# psc3 register map
Vendor: Infineon Technologies; Series: PSC3; File version: 1.0
CPU: CM33 r0p1, little endian, MPU, FPU, VTOR, 3 interrupt priority bits
Registers are 32-bit, read-write, reset 0x0 unless marked. A register's access mark holds for its fields unless they carry their own. Offsets are from the block's base; [hi:lo] are bit positions; {n}, {i} and the like mark numbered series; 'fields as' and 'values as' point back to an identical list.

## SRSS (part 1 of 3) — SRSS Core Registers
Base 0x42200000
0x40 PWR_LVD_STATUS ro — High Voltage / Low Voltage Detector (HVLVD) Status Register
  [0] HVLVD1_OK — HVLVD1 output. 0: below voltage threshold 1: above voltage threshold
0x44 PWR_LVD_STATUS2 ro — High Voltage / Low Voltage Detector (HVLVD) Status Register #2
  [0] HVLVD2_OUT — HVLVD2 output. 0: below voltage threshold 1: above voltage threshold
{0x100+4i} CLK_DSI_SELECT[{i}] (i=0..15) — Clock DSI Select Register
  [4:0] DSI_MUX — Selects a DSI source or low frequency clock for use in a clock path. The output of this mux can be selected for clock PATH<i> using CLK_SELECT_PATH register. Using the output of this mux as HFCLK source will result in undefined behavior. It can be used to clocks to DSI or as reference inputs for the FLL/PLL, subject to the frequency limits of those circuits. This mux is not glitch free, so do not change the selection while it is an actively selected clock.
    {v}=DSI_OUT{v} (DSI{v} - dsi_out[{v}]) (v=0..15); 16=ILO (ILO - Internal Low-speed Oscillator #0); 17=WCO (WCO - Watch-Crystal Oscillator); 18=ALTLF (ALTLF - Alternate Low-Frequency Clock); 19=PILO (PILO - Precision Internal Low-speed Oscillator); 20=ILO1 (ILO1 - Internal Low-speed Oscillator #1, if present.)
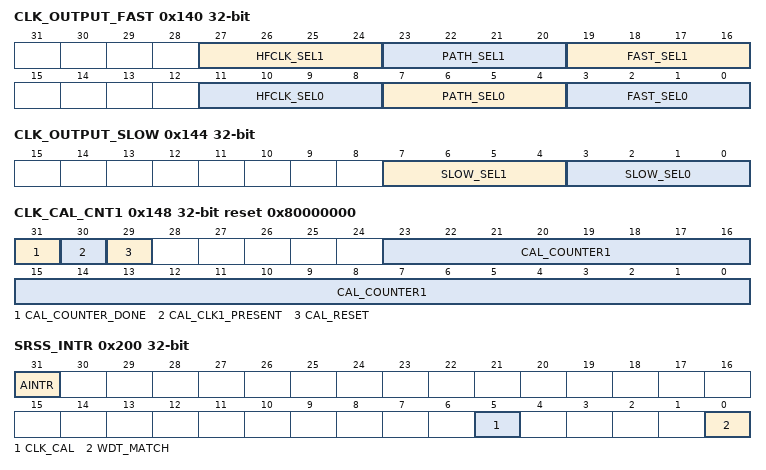
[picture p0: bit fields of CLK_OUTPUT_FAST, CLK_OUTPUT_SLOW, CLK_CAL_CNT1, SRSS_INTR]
0x140 CLK_OUTPUT_FAST — Fast Clock Output Select Register
  [27:24] HFCLK_SEL1 — Selects a HFCLK tree for use in fast clock output #1 logic
  [23:20] PATH_SEL1 — Selects a clock path to use in fast clock output #1 logic.
  [19:16] FAST_SEL1 — Select signal for fast clock output #1
    0=NC (Disabled - output is 0. For power savings, clocks are blocked before entering any muxes, including PATH_SEL1 and HFCLK_SEL1.); 1=ECO (External Crystal Oscillator (ECO)); 2=EXTCLK (External clock input (EXTCLK)); 3=ALTHF (Alternate High-Frequency (ALTHF) clock input to SRSS); 4=TIMERCLK (Timer clock. It is grouped with the fast clocks because it may be a gated version of a fast clock, and therefore may have a short high pulse.); 5=PATH_SEL1 (Selects the clock path chosen by PATH_SEL1 field); 6=HFCLK_SEL1 (Selects the output of the HFCLK_SEL1 mux); 7=SLOW_SEL1 (Selects the output of CLK_OUTPUT_SLOW.SLOW_SEL1); 8=IHO (Internal High-speed Oscillator (IHO).); 9=PWR (clk_pwr: used for PPU and related components)
  [11:8] HFCLK_SEL0 — Selects a HFCLK tree for use in fast clock output #0
  [7:4] PATH_SEL0 — Selects a clock path to use in fast clock output #0 logic.
  [3:0] FAST_SEL0 — Select signal for fast clock output #0
    0=NC (Disabled - output is 0. For power savings, clocks are blocked before entering any muxes, including PATH_SEL0 and HFCLK_SEL0.); 1=ECO (External Crystal Oscillator (ECO)); 2=EXTCLK (External clock input (EXTCLK)); 3=ALTHF (Alternate High-Frequency (ALTHF) clock input to SRSS); 4=TIMERCLK (Timer clock. It is grouped with the fast clocks because it may be a gated version of a fast clock, and therefore may have a short high pulse.); 5=PATH_SEL0 (Selects the clock path chosen by PATH_SEL0 field); 6=HFCLK_SEL0 (Selects the output of the HFCLK_SEL0 mux); 7=SLOW_SEL0 (Selects the output of CLK_OUTPUT_SLOW.SLOW_SEL0); 8=IHO (Internal High-speed Oscillator (IHO).); 9=PWR (clk_pwr: used for PPU and related components)
0x144 CLK_OUTPUT_SLOW — Slow Clock Output Select Register
  [7:4] SLOW_SEL1 — Select signal for slow clock output #1
    0=NC (Disabled - output is 0. For power savings, clocks are blocked before entering any muxes.); 1=ILO (Internal Low Speed Oscillator (ILO)); 2=WCO (Watch-Crystal Oscillator (WCO)); 3=BAK (Root of the Backup domain clock tree (BAK)); 4=ALTLF (Alternate low-frequency clock input to SRSS (ALTLF)); 5=LFCLK (Root of the low-speed clock tree (LFCLK)); 6=IMO (Internal Main Oscillator (IMO). This is grouped with the slow clocks so it can be observed during DEEPSLEEP entry/exit.); 7=SLPCTRL (Sleep Controller clock (SLPCTRL). This is grouped with the slow clocks so it can be observed during DEEPSLEEP entry/exit.); 8=PILO (Precision Internal Low Speed Oscillator (PILO)); 9=ILO1 (Internal Low Speed Oscillator (ILO1), if present on the product.); 10=ECO_PRESCALER (ECO Prescaler (ECO_PRESCALER)); 11=LPECO; 12=LPECO_PRESCALER (LPECO Prescaler (LPECO_PRESCALER)); 13=MFO (Medium Frequency Oscillator (MFO))
  [3:0] SLOW_SEL0 — Select signal for slow clock output #0
    values as SLOW_SEL1
0x148 CLK_CAL_CNT1 reset 0x80000000 — Clock Calibration Counter 1
  [31] CAL_COUNTER_DONE ro — Status bit indicating that the internal counter #1 is finished counting and CLK_CAL_CNT2.COUNTER stopped counting up
  [30] CAL_CLK1_PRESENT ro — Status bit indicating that a posedge was detected by counter #1. If this bit never asserts, there is no clock on counter #1 and CAL_COUNTER_DONE will stay low indefinitely. This can be recovered with CAL_RESET.
  [29] CAL_RESET — Reset clock calibration logic for window mode. This can be used to recover from unexpected conditions, such as no clock present on counter #1. Set this bit only when CLK_CAL_TEST.CAL_WINDOW_SEL=1 (window mode). It takes 3 clock cycles for reset to propagate.
  [23:0] CAL_COUNTER1 — Down-counter clocked on fast clock output #0 (see CLK_OUTPUT_FAST). This register always reads as zero. Counting starts internally when this register is written with a nonzero value. CAL_COUNTER_DONE goes immediately low to indicate that the counter has started and will be asserted when the counters are done. Do not write this field unless CAL_COUNTER_DONE==1. Both clocks must be running or the measurement will not complete, and this case can be recovered using CAL_RESET.
0x14C CLK_CAL_CNT2 ro — Clock Calibration Counter 2
  [23:0] CAL_COUNTER2 — Up-counter clocked on fast clock output #1 (see CLK_OUTPUT_FAST). When CLK_CAL_CNT1.CAL_COUNTER_DONE==1, the counter is stopped and can be read by SW. Do not read this value unless CAL_COUNTER_DONE==1. The expected final value is related to the ratio of clock frequencies used for the two counters and the value loaded into counter 1: CLK_CAL_CNT2.COUNTER=(F_cnt2/F_cnt1)*(CLK_CAL_CNT1.COUNTER)
0x200 SRSS_INTR — SRSS Interrupt Register
  [31] AINTR ro — See additional interrupts in SRSS_AINTR.
  [5] CLK_CAL — Clock calibration counter is done. This field is reset during DEEPSLEEP mode.
  [0] WDT_MATCH — WDT Interrupt Request. This bit is set each time WDT_COUNTR==WDT_MATCH. W1C also feeds the watch dog. Missing 2 interrupts in a row will generate a reset. Due to internal synchronization, it takes 2 SYSCLK cycles to update after a W1C.
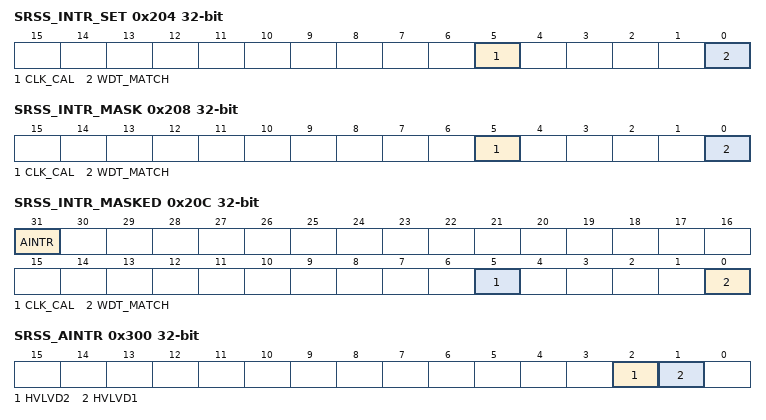
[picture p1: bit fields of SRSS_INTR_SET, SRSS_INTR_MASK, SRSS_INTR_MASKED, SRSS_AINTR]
0x204 SRSS_INTR_SET — SRSS Interrupt Set Register
  [5] CLK_CAL — Set interrupt for clock calibration counter done. This field is reset during DEEPSLEEP mode.
  [0] WDT_MATCH — Set interrupt for low voltage detector WDT_MATCH
0x208 SRSS_INTR_MASK — SRSS Interrupt Mask Register
  [5] CLK_CAL — Mask for clock calibration done
  [0] WDT_MATCH — Mask for watchdog timer. Clearing this bit will not forward the interrupt to the CPU. It will not, however, disable the WDT reset generation on 2 missed interrupts. When WDT resets the chip, it also internally pends an interrupt that survives the reset. To prevent unintended ISR execution, clear SRSS_INTR.WDT_MATCH before setting this bit.
0x20C SRSS_INTR_MASKED ro — SRSS Interrupt Masked Register
  [31] AINTR — See additional MASKED bits in SRSS_AINTR_MASKED.ADDITIONAL
  [5] CLK_CAL — Logical and of corresponding request and mask bits.
  [0] WDT_MATCH — Logical and of corresponding request and mask bits.
0x300 SRSS_AINTR — SRSS Additional Interrupt Register
  [2] HVLVD2 — Interrupt for low voltage detector HVLVD2
  [1] HVLVD1 — Interrupt for low voltage detector HVLVD1
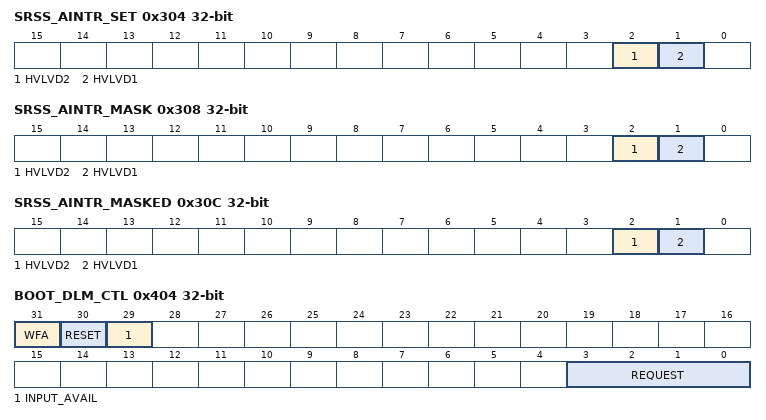
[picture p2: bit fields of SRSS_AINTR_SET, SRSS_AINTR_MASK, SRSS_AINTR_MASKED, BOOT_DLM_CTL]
0x304 SRSS_AINTR_SET — SRSS Additional Interrupt Set Register
  [2] HVLVD2 — Set interrupt for low voltage detector HVLVD2
  [1] HVLVD1 — Set interrupt for low voltage detector HVLVD1
0x308 SRSS_AINTR_MASK — SRSS Additional Interrupt Mask Register
  [2] HVLVD2 — Mask for low voltage detector HVLVD2
  [1] HVLVD1 — Mask for low voltage detector HVLVD1
0x30C SRSS_AINTR_MASKED ro — SRSS Additional Interrupt Masked Register
  [2] HVLVD2 — Logical and of corresponding request and mask bits.
  [1] HVLVD1 — Logical and of corresponding request and mask bits.
0x404 BOOT_DLM_CTL — Debug Control Register
  [31] WFA — Wait for Action. Set by BootROM when it waits for application or debug certificate to be loaded into the RAM. The bit must be cleared to continue BootROM operation. It is used by the Sys-AP.
  [30] RESET — Request the device reset after RAM application complete input parameters processing. This bit is analyzed with APP_INPUT_AVAIL so to take effect write both. 0 - No action, the device waits for input parameters. 1 - Reset the device after input parameters processing complete.
  [29] INPUT_AVAIL — Notify RAM application that input parameters are valid for processing: 0 - the input parameters are not available. 1 - the input parameters are available (ready) for processing.
  [3:0] REQUEST — A request to ROM_BOOT FW to execute particular code. This field survives some resets, including a system reset: * 0 - No request (default). * 1 - ROM_BOOT to wait for DLM app (PC=0). * 2 - ROM_BOOT to wait for an OEM debug token. * 3 - ROM_BOOT to wait for a PROT_FW debug token. * 4, 5 - ignored by ROM_BOOT. * 6 - ROM_BOOT to launch DLM app which has been downloaded by DFU. * 7 - ROM_BOOT to respond to DFU with DLM app status. Other: ignored by ROM_BOOT.
0x408 BOOT_DLM_CTL2 — Debug Control Register 2
  [31:0] APP_CTL — Address of application descriptor or debug certificate depends on DEBUG_TST_CTL.REQUEST. The application descriptor provides info about RAM application and its parameters layout in the staging area to BootROM and RAM application itself
0x40C BOOT_DLM_STATUS — Debug Status Register
  [31:0] DEBUG_STATUS — RAM application execution status. This status can be read by the debugger using Sys-AP or user application when RAM application completes with system reset. This field survives some resets, including a system reset.
0x410 RES_SOFT_CTL — Soft Reset Trigger Register
  [0] TRIGGER_SOFT — Triggers a soft reset. The reset clears this bit.
0x418 BOOT_STATUS — Boot Execution Status Register
  [31:0] DEBUG_STATUS — Boot execution status. This status register can be used for communication between ROM_BOOT and User Application. This status can be read by the debugger using Sys-AP or User Application. This field survives some resets, including a system reset.
0x430 BOOT_ENTRY — Warm Boot Entry Address
  [31:0] WARM_BOOT_ENTRY — Warm boot entry point. This status register can be used for communication between 2 software application before/after DS-RAM or soft reset. This field survives low voltage resets, including a system reset.
{0x800+4i} PWR_HIB_DATA[{i}] (i=0..15) — HIBERNATE Data Register
  [31:0] HIB_DATA — Additional data that is retained through a HIBERNATE/WAKEUP sequence that can be used by firmware for any application-specific purpose. Note that waking up from HIBERNATE using XRES will reset this register.
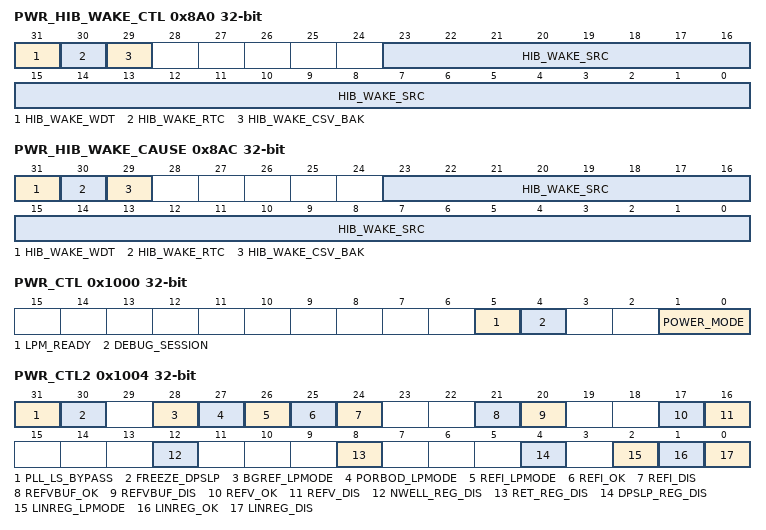
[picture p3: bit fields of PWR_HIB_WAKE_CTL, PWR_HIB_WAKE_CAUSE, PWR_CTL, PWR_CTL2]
0x8A0 PWR_HIB_WAKE_CTL — Hibernate Wakeup Mask Register
  [31] HIB_WAKE_WDT — When set, HIBERNATE will wakeup for a pending WDT interrupt.
  [30] HIB_WAKE_RTC — When set, HIBERNATE will wakeup for a pending RTC interrupt.
  [29] HIB_WAKE_CSV_BAK — When set, HIBERNATE will wakeup for CSV_BAK detection.
  [23:0] HIB_WAKE_SRC — When set, HIBERNATE will wakeup for the assigned source.
0x8A4 PWR_HIB_WAKE_CTL2 — Hibernate Wakeup Polarity Register
  [23:0] HIB_WAKE_SRC — Each bit selects the polarity for the corresponding HIBERNATE wakeup source. 0: Wakes when unmasked input is 0. 1: Wakes when unmasked input is 1.
0x8AC PWR_HIB_WAKE_CAUSE — Hibernate Wakeup Cause Register
  [31] HIB_WAKE_WDT — Indicates WDT wakeup cause. The WDT interrupt must be cleared before this bit can be cleared.
  [30] HIB_WAKE_RTC — Indicates RTC wakeup cause. The RTC interrupt must be cleared before this bit can be cleared.
  [29] HIB_WAKE_CSV_BAK — Indicates CSV_BAK wakeup cause. The related fault must be handled before this bit can be cleared.
  [23:0] HIB_WAKE_SRC — Each bit indicates a HIBERNATE wakeup cause. For each bit, writing a 1 clears the cause flag.
0x1000 PWR_CTL ro — Power Mode Control
  [5] LPM_READY — Indicates whether certain low power functions are ready. The low current circuits take longer to startup after XRES, HIBERNATE wakeup, or supply supervision reset wakeup than the normal mode circuits. HIBERNATE mode may be entered regardless of this bit. 0: If a low power circuit operation is requested, it will stay in its normal operating mode until it is ready. If DEEPSLEEP is requested by all processors WFI/WFE, the device will instead enter SLEEP. When low power circuits are ready, device will automatically enter the originally requested mode. 1: Normal operation. DEEPSLEEP and low power circuits operate as requested in other registers.
  [4] DEBUG_SESSION — Indicates whether a debug session is active (CDBGPWRUPREQ signal is 1)
    0=NO_SESSION (No debug session active); 1=SESSION_ACTIVE (Debug session is active. Power modes behave differently to keep the debug session active, and current consumption may be higher than datasheet specification.)
  [1:0] POWER_MODE — Current power mode of the device. Note that this field cannot be read in all power modes on actual silicon.
    0=RESET (System is resetting.); 1=ACTIVE (At least one CPU is running.); 2=SLEEP (No CPUs are running. Peripherals may be running.); 3=DEEPSLEEP (Main high-frequency clock is off; low speed clocks are available. Communication interface clocks may be present.)
0x1004 PWR_CTL2 — Power Mode Control 2
  [31] PLL_LS_BYPASS — Bypass level shifter inside the PLL. Unused, if no PLL is present in the product. Note that this only applies to PLL200M. 0: Do not bypass the level shifter. This setting is ok for all operational modes and vccd target voltage. 1: Bypass the level shifter. This may reduce jitter on the PLL output clock, but can only be used when vccd is targeted to 1.1V nominal. Otherwise, it can result in clock degradation and static current.
  [30] FREEZE_DPSLP — Controls whether mode and state of GPIOs and SIOs in the system are frozen. This is intended to be used as part of the DEEPSLEEP-RAM and DEEPSLEEP-OFF entry and exit sequences. It is set by HW while entering DEEPSLEEP-RAM and DEEPSLEEP-OFF modes. Writing a 1 clears freeze and GPIOs and SIOs resume normal operation.
  [28] BGREF_LPMODE — Control the circuit-level power mode of the Bandgap Reference circuits for higher operating modes than DEEPSLEEP. This selects a second set of bandgap voltage and current generation circuits that are optimized for low current consumption. The low current circuits are automatically used in DEEPSLEEP mode regardless of this bit. The value in this register is ignored and higher-current mode is used until LPM_READY==1. After this bit is set, the Active Reference circuit can be disabled to reduce current (ACT_REF_DIS=0). Firmware is responsible to enable the Active Reference and ensure ACT_REF_OK==1 before changing back to higher current mode. This register is only reset by XRES, HIBERNATE wakeup, or supply supervision reset. 0: Bandgap Reference uses the normal settings. 1: Bandgap Reference uses the low power DeepSleep circuits. Power supply rejection is reduced to save current.
  [27] PORBOD_LPMODE — Control the power mode of the POR/BOD circuits. The value in this register is ignored and normal mode is used until LPM_READY==1. This register is only reset by XRES, HIBERNATE wakeup, or supply supervision reset. 0: POR/BOD circuits operate in normal mode. 1: POR/BOD circuits operate in low power mode. Response time is reduced to save current.
  [26] REFI_LPMODE — Control the power mode of the reference current generator. The value in this register is ignored and normal mode is used until LPM_READY==1. This register is only reset by XRES, HIBERNATE wakeup, or supply supervision reset. 0: Current reference generator operates in normal mode. 1: Current reference generator operates in low power mode. Response time is reduced to save current.
  [25] REFI_OK ro — Indicates that the current reference is ready. Due to synchronization delays, it may take two IMO clock cycles for hardware to clear this bit after asserting REFI_DIS=1.
  [24] REFI_DIS
  [21] REFVBUF_OK ro — Indicates that the voltage reference buffer is ready. Due to synchronization delays, it may take two IMO clock cycles for hardware to clear this bit after asserting REFVBUF_DIS=1.
  [20] REFVBUF_DIS — Disable the voltage reference buffer. Firmware should only disable the buffer when there is no connected circuit that is using it. SRSS circuits that require it are the PLL and ECO. A particular product may have circuits outside the SRSS that use the buffer. This register is only reset by XRES, HIBERNATE wakeup, or supply supervision reset.
  [17] REFV_OK ro — Indicates that the normal mode of the voltage reference is ready.
  [16] REFV_DIS
  [12] NWELL_REG_DIS — Explicitly disable the Nwell regulator. This register should normally be zero, except for special sequences provided by Infineon to use a different regulator. This register is only reset by XRES, HIBERNATE wakeup, or supply supervision reset. 0: Nwell Regulator is on. Hardware disables it automatically for internal sequences, including for HIBERNATE and XRES low power modes. Hardware keeps the Nwell Regulator enabled during ACTIVE/SLEEP modes, so it is ready to enter DEEPSLEEP at any time. 1: Nwell Regulator is explicitly disabled. Only use this for special cases when another source supplies vnwell during DEEPSLEEP mode. This setting is only legal when another source supplies vnwell, but there is no special hardware protection for this case.
  [8] RET_REG_DIS — Explicitly disable the Retention regulator. This field should normally be zero, except for special sequences provided by Infineon to use a different regulator. This register is only reset by XRES, HIBERNATE wakeup, or supply supervision reset. 0: Retention Regulator is not explicitly disabled. Hardware disables it automatically for internal sequences, including for HIBERNATE and XRES low power modes. Hardware keeps the Retention Regulator enabled during ACTIVE/SLEEP modes, so it is ready to enter DEEPSLEEP at any time. 1: Retention Regulator is explicitly disabled. Only use this for special cases when another source supplies vccret during DEEPSLEEP mode. This setting is only legal when another source supplies vccret, but there is no special hardware protection for this case.
  [4] DPSLP_REG_DIS — Explicity disable the DeepSleep regulator, including circuits shared with the Active Regulator. This register must not be set except as part of an Infineon-provided sequence or API. This register is only reset by XRES, HIBERNATE wakeup, or supply supervision reset. 0: DeepSleep Regulator is not explicitly disabled. This is the normal setting, and hardware automatically controls the DeepSleep regulator for most sequences, including for HIBERNATE and XRES low power modes. This setting must be used if the Active Linear Regulator is used, because some circuitry is shared. 1: DeepSleep Regulator is explicitly disabled. Only use this for special cases as part of an Infineon-provided handoff to another supply source. For example, this setting may be used when another source supplies vccdpslp during DEEPSLEEP mode and the Active Linear Regulator is not usedfor ACTIVE/SLEEP modes.
  [2] LINREG_LPMODE — Control the power mode of the Linear Regulator. The value in this register is ignored and normal mode is used until LPM_READY==1. This register is only reset by XRES, HIBERNATE wakeup, or supply supervision reset. 0: Linear Regulator operates in normal mode. 1: Linear Regulator operates in low power mode. Load current capability is reduced, and firmware must ensure the current is kept within the limit.
  [1] LINREG_OK ro — Status of the linear Core Regulator.
  [0] LINREG_DIS — Explicitly disable the linear Core Regulator. Write zero for Traveo II devices. This register is only reset by XRES, HIBERNATE wakeup, or supply supervision reset. 0: Linear Core Regulator is not explicitly disabled. Hardware disables it automatically for internal sequences, including for DEEPSLEEP, HIBERNATE, and XRES low power modes. 1: Linear Core Regulator is explicitly disabled. Only use this for special cases when another source supplies vccd during ACTIVE and SLEEP modes. This setting is only legal when another source supplies vccd, but there is no special hardware protection for this case.
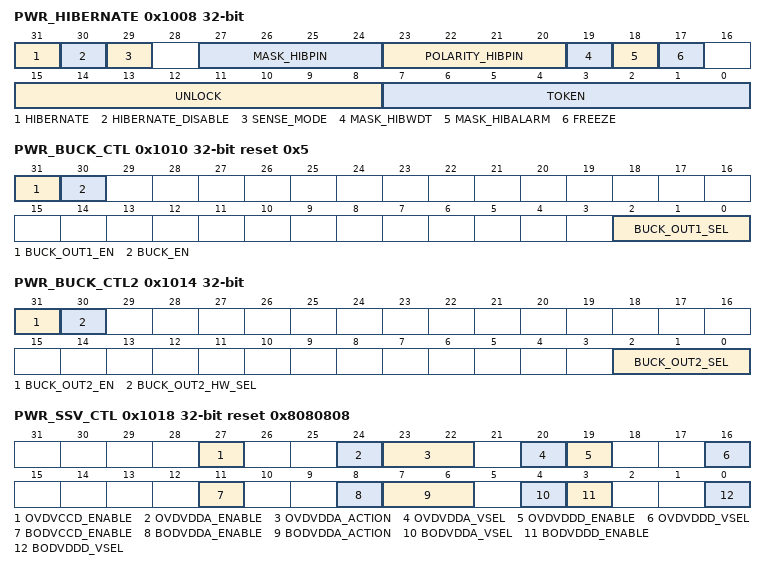
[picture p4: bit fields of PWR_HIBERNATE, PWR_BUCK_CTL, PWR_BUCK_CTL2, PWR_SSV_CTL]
0x1008 PWR_HIBERNATE — HIBERNATE Mode Register
  [31] HIBERNATE — Firmware sets this bit to enter HIBERNATE mode. The system will enter HIBERNATE mode immediately after writing to this bit and will wakeup only in response to XRES or WAKEUP. Both UNLOCK and FREEZE must have been set correctly in a previous write operations. Otherwise, it will not enter HIBERNATE. External supplies must have been stable for 250us before entering HIBERNATE mode.
  [30] HIBERNATE_DISABLE — Hibernate disable bit. 0: Normal operation, HIBERNATE works as described 1: Further writes to this register are ignored Note: This bit is a write-once bit until the next reset. Avoid changing any other bits in this register while disabling HIBERNATE mode. Also, it is recommended to clear the UNLOCK code, if it was previously written..
  [29] SENSE_MODE — Power mode when wakeups are sensitive. The default of this field is 0 for software compatibility with other products. It is recommended to set this field to 1 for new/updated software. 0: Wakeups are sensitive only during HIBERNATE mode. A wakeup pulse that comes just before HIBERNATE entry may be missed. Backward compatible. 1: Wakeups are sensitive in HIBERNATE and higher modes. Before entering HIBERNATE, software must clear all unmasked, pending wakeups in PWR_HIB_WAKE_CAUSE register. An unmasked, pending wakeup causes HIBERNATE wakeup, even if it was pending from before HIBERNATE entry. This prevents missed wakeups.
  [27:24] MASK_HIBPIN
  [23:20] POLARITY_HIBPIN
  [19] MASK_HIBWDT
  [18] MASK_HIBALARM
  [17] FREEZE — Controls whether mode and state of GPIOs and SIOs in the system are frozen. This is intended to be used as part of the HIBERNATE entry and exit sequences. When entering HIBERNATE mode, the first write instructs DEEPSLEEP peripherals that they cannot ignore the upcoming freeze command. This occurs even in the illegal condition where UNLOCK is not set. If UNLOCK and HIBERNATE are properly set, the IOs actually freeze on the second write. Supply supervision is disabled during HIBERNATE mode. HIBERNATE peripherals ignore resets (excluding XRES) while FREEZE==1.
  [15:8] UNLOCK — This byte must be set to 0x3A for FREEZE or HIBERNATE fields to operate. Any other value in this register will cause FREEZE/HIBERNATE to have no effect, except as noted in the FREEZE description.
  [7:0] TOKEN — Contains a 8-bit token that is retained through a HIBERNATE/WAKEUP sequence that can be used by firmware to differentiate WAKEUP from a general RESET event. Note that waking up from HIBERNATE using XRES will reset this register.
0x1010 PWR_BUCK_CTL reset 0x5 — Buck Control Register
  [31] BUCK_OUT1_EN — Enable for vccbuck1 output. The value in this register is ignored unless PWR_BUCK_CTL.BUCK_EN==1. This register is only reset by XRES, HIBERNATE wakeup, or supply supervision reset. The regulator takes up to 600us to charge the external capacitor. If there is additional load current while charging, this will increase the startup time. The TRM specifies the required sequence when transitioning vccd from the LDO to SIMO Buck output #1.
  [30] BUCK_EN — Master enable for buck converter. This register is only reset by XRES, HIBERNATE wakeup, or supply supervision reset.
  [2:0] BUCK_OUT1_SEL — Voltage output selection for vccbuck1 output. This register is only reset by XRES, HIBERNATE wakeup, or supply supervision reset. When increasing the voltage, it can take up to 200us for the output voltage to settle. When decreasing the voltage, the settling time depends on the load current. 0: 0.85V 1: 0.875V 2: 0.90V 3: 1.0V (SISO-MC), 0.95V (SISO-LC, SIMO-LC) 4: 1.05V 5: 1.10V 6: 1.15V 7: 1.20V
0x1014 PWR_BUCK_CTL2 — Buck Control Register 2
  [31] BUCK_OUT2_EN — Enable for vccbuck2 output. The value in this register is ignored unless PWR_BUCK_CTL.BUCK_EN==1. The regulator takes up to 600us to charge the external capacitor. If there is additional load current while charging, this will increase the startup time.
  [30] BUCK_OUT2_HW_SEL — Hardware control for vccbuck2 output. When this bit is set, the value in BUCK_OUT2_EN is ignored and a hardware signal is used instead. If the product has supporting hardware, it can directly control the enable signal for vccbuck2. The same charging time in BUCK_OUT2_EN applies.
  [2:0] BUCK_OUT2_SEL — Voltage output selection for vccbuck2 output. When increasing the voltage, it can take up to 200us for the output voltage to settle. When decreasing the voltage, the settling time depends on the load current. 0: 1.15V 1: 1.20V 2: 1.25V 3: 1.30V 4: 1.35V 5: 1.40V 6: 1.45V 7: 1.50V
0x1018 PWR_SSV_CTL reset 0x8080808 — Supply Supervision Control Register
  [27] OVDVCCD_ENABLE — Enable for OVD on vccd. This cannot be disabled during normal operation.
  [24] OVDVDDA_ENABLE — Enable for OVD on vdda.
  [23:22] OVDVDDA_ACTION — Action taken when the OVD on vdda triggers.
    0=NOTHING (No action); 1=FAULT (Generate a fault); 2=RESET (Reset the chip)
  [20] OVDVDDA_VSEL — Selects the voltage threshold for OVD on vdda. Ensure OVDVDDA_ENABLE==0 before changing this setting to prevent false triggers 0: vddd>5.5V 1: vddd>5.0V
  [19] OVDVDDD_ENABLE — Enable for OVD on vddd. This cannot be disabled during normal operation.
  [16] OVDVDDD_VSEL — Selects the voltage threshold for OVD on vddd. The OVD does not reliably monitor the supply during the transition. 0: vddd>5.5V 1: vddd>5.0V
  [11] BODVCCD_ENABLE — Enable for BOD on vccd. This cannot be disabled during normal operation.
  [8] BODVDDA_ENABLE — Enable for BOD on vdda. BODVDDA_ACTION will be triggered when the BOD is disabled. If no action is desired when disabling, firmware must first write BODVDDA_ACTION=NOTHING in a separate write cycle.
  [7:6] BODVDDA_ACTION — Action taken when the BOD on vdda triggers.
    values as OVDVDDA_ACTION
  [4] BODVDDA_VSEL — Selects the voltage threshold for BOD on vdda. Ensure BODVDDA_ENABLE==0 before changing this setting to prevent false triggers. 0: vdda<2.7V 1: vdda<3.0V
  [3] BODVDDD_ENABLE — Enable for BOD on vddd. This cannot be disabled during normal operation.
  [0] BODVDDD_VSEL — Selects the voltage threshold for BOD on vddd. The BOD does not reliably monitor the supply during the transition. 0: vddd<2.7V 1: vddd<3.0V
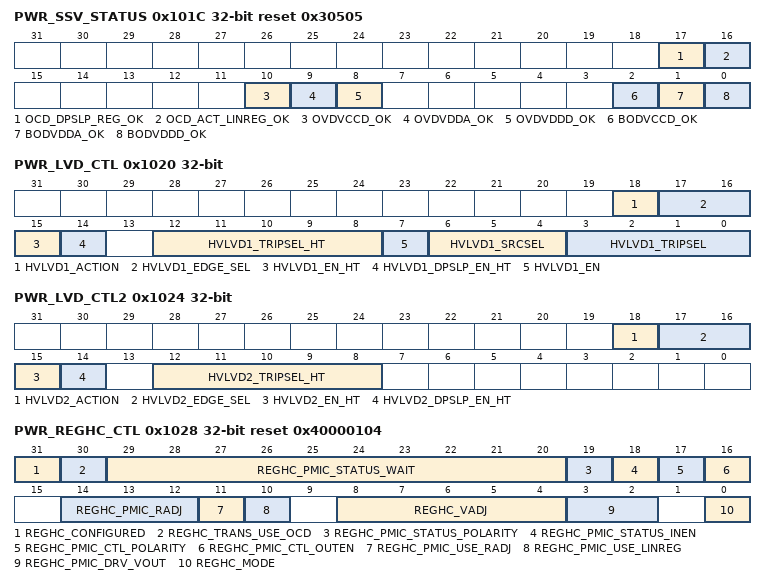
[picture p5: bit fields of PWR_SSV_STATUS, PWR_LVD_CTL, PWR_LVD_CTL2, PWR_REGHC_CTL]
0x101C PWR_SSV_STATUS ro reset 0x30505 — Supply Supervision Status Register
  [17] OCD_DPSLP_REG_OK — OCD indicates the current drawn from the linear DeepSleep Regulator is ok. This will always read 1, because a detected over-current condition will reset the chip.
  [16] OCD_ACT_LINREG_OK — OCD indicates the current drawn from the linear Active Regulator is ok. This will always read 1, because a detected over-current condition will reset the chip.
  [10] OVDVCCD_OK — OVD indicates vccd is ok. This will always read 1, because a detected over-over-voltage condition will reset the chip.
  [9] OVDVDDA_OK — OVD indicates vdda is ok.
  [8] OVDVDDD_OK — OVD indicates vddd is ok. This will always read 1, because a detected over-voltage condition will reset the chip.
  [2] BODVCCD_OK — BOD indicates vccd is ok. This will always read 1, because a detected brownout will reset the chip.
  [1] BODVDDA_OK — BOD indicates vdda is ok.
  [0] BODVDDD_OK — BOD indicates vddd is ok. This will always read 1, because a detected brownout will reset the chip.
0x1020 PWR_LVD_CTL — High Voltage / Low Voltage Detector (HVLVD) Configuration Register
  [18] HVLVD1_ACTION — Action taken when the threshold is crossed in the programmed directions(s)
    0=INTERRUPT (Generate an interrupt); 1=FAULT (Generate a fault)
  [17:16] HVLVD1_EDGE_SEL — Sets which edge(s) will trigger an action when the threshold is crossed.
    0=DISABLE (Disabled); 1=RISING (Rising edge); 2=FALLING (Falling edge); 3=BOTH (Both rising and falling edges)
  [15] HVLVD1_EN_HT — Enable HVLVD1 voltage monitor. This detector monitors vddd only. Do not change other HVLVD1 settings when enabled.
  [14] HVLVD1_DPSLP_EN_HT — Keep HVLVD1 voltage monitor enabled during DEEPSLEEP mode. This field is only used when HVLVD1_EN_HT==1.
  [12:8] HVLVD1_TRIPSEL_HT
  [7] HVLVD1_EN — Enable HVLVD1 voltage monitor. HVLVD1 does not function during DEEPSLEEP, but it automatically returns to its configured setting after DEEPSLEEP wakeup. Do not change other HVLVD1 settings when enabled.
  [6:4] HVLVD1_SRCSEL — Source selection for HVLVD1
    0=VDDD (Select VDDD); 1=AMUXBUSA (Select AMUXBUSA (VDDD branch)); 2=RSVD (N/A); 3=VDDIO (N/A); 4=AMUXBUSB (Select AMUXBUSB (VDDD branch))
  [3:0] HVLVD1_TRIPSEL — Threshold selection for HVLVD1. Disable the detector (HVLVD1_EN=0) before changing the threshold. 0: rise=1.225V (nom), fall=1.2V (nom) 1: rise=1.425V (nom), fall=1.4V (nom) 2: rise=1.625V (nom), fall=1.6V (nom) 3: rise=1.825V (nom), fall=1.8V (nom) 4: rise=2.025V (nom), fall=2V (nom) 5: rise=2.125V (nom), fall=2.1V (nom) 6: rise=2.225V (nom), fall=2.2V (nom) 7: rise=2.325V (nom), fall=2.3V (nom) 8: rise=2.425V (nom), fall=2.4V (nom) 9: rise=2.525V (nom), fall=2.5V (nom) 10: rise=2.625V (nom), fall=2.6V (nom) 11: rise=2.725V (nom), fall=2.7V (nom) 12: rise=2.825V (nom), fall=2.8V (nom) 13: rise=2.925V (nom), fall=2.9V (nom) 14: rise=3.025V (nom), fall=3.0V (nom) 15: rise=3.125V (nom), fall=3.1V (nom)
0x1024 PWR_LVD_CTL2 — High Voltage / Low Voltage Detector (HVLVD) Configuration Register #2
  [18] HVLVD2_ACTION — Action taken when the threshold is crossed in the programmed directions(s)
    values as PWR_LVD_CTL.HVLVD1_ACTION
  [17:16] HVLVD2_EDGE_SEL — Sets which edge(s) will trigger an action when the threshold is crossed.
    values as PWR_LVD_CTL.HVLVD1_EDGE_SEL
  [15] HVLVD2_EN_HT — Enable HVLVD2 voltage monitor. This detector monitors vddd only. Do not change other HVLVD2 settings when enabled.
  [14] HVLVD2_DPSLP_EN_HT — Keep HVLVD2 voltage monitor enabled during DEEPSLEEP mode. This field is only used when HVLVD1_EN_HT==1.
  [12:8] HVLVD2_TRIPSEL_HT
0x1028 PWR_REGHC_CTL reset 0x40000104 — REGHC Control Register
  [31] REGHC_CONFIGURED — Indicates the REGHC has been configured. This is used to know if REGHC should be enabled in response to a debug power up request. Do not change REGHC settings after this bit is set high.
  [30] REGHC_TRANS_USE_OCD
  [29:20] REGHC_PMIC_STATUS_WAIT — Wait count in 4us steps after PMIC status ok. This is used by the hardware sequencer to allow additional settling time before disabling the internal regulator. The LSB is 32 IMO periods which results in a nominal LSB step of 4us.
  [19] REGHC_PMIC_STATUS_POLARITY — The polarity used to trigger a reset action based on the PMIC status input. The reset system triggers a reset when the unmasked PMIC status matches this value.
  [18] REGHC_PMIC_STATUS_INEN — Input buffer enable for PMIC status input. Set this bit high to enable the input receiver.
  [17] REGHC_PMIC_CTL_POLARITY — Polarity used to enable the PMIC. The sequencer uses REGHC_PMIC_CTL_POLARITY to enable the PMIC, and it uses the complement to disable the PMIC.
  [16] REGHC_PMIC_CTL_OUTEN — Output enable for PMIC enable pin. Set this bit high to enable the driver on this pin.
  [14:12] REGHC_PMIC_RADJ — Reset voltage adjustment for PMIC as a factor (Vfbk/Vref) where Vfbk is the feedback voltage and Vref is the PMIC internal reference. The reset voltage adjustment circuit is enabled by the hardware sequencer if REGHC_PMIC_USE_RADJ=1. PMIC have Vref of 0.8V or 0.9V, and the resulting reset voltage (Vreset) are precalculated in the table below: 3'b000: Vfbk/Vref=1.0000, Vreset=.800V@(Vref=0.8V), .900V@(Vref=0.9V); 3'b001: Vfbk/Vref=1.0556, Vreset=.844V@(Vref=0.8V), .950V@(Vref=0.9V); 3'b010: Vfbk/Vref=1.1111, Vreset=.889V@(Vref=0.8V), 1.000V@(Vref=0.9V); 3'b011: Vfbk/Vref=1.1250, Vreset=.900V@(Vref=0.8V), 1.013V@(Vref=0.9V); 3'b100: Vfbk/Vref=1.1667, Vreset=.933V@(Vref=0.8V), 1.050V@(Vref=0.9V); 3'b101: Vfbk/Vref=1.1875, Vreset=.950V@(Vref=0.8V), 1.069V@(Vref=0.9V); 3'b110: Vfbk/Vref=1.2500, Vreset=1.000V@(Vref=0.8V), 1.125V@(Vref=0.9V); 3'b111: Vfbk/Vref=1.3125, Vreset=1.050V@(Vref=0.8V), 1.181V@(Vref=0.9V);
  [11] REGHC_PMIC_USE_RADJ — Controls whether hardware sequencer enables reset voltage adjustment circuit when enabling a PMIC.
  [10] REGHC_PMIC_USE_LINREG — For REGHC external PMIC mode, controls whether hardware sequencer keeps the internal Active Linear Regulator enabled to improve supply supervision of vccd. When using this feature, if the PMIC fails to keep vccd above the internal regulator target, then the internal regulator will attempt to recover vccd. If the regulator current is too high, the regulator triggers an over-current detector (OCD) reset. 0: Internal Active Linear Regulator disabled after PMIC enabled. OCD is disabled.; 1: Internal Active Linear Regulator kept enabled. See datasheet for minimum PMIC vccd input to prevent OCD.
  [8:4] REGHC_VADJ — Regulator output trim according to the formula vadj=(1.020V + REGHC_VADJ*0.005V). The default is 1.1V. For transistor mode, REGHC will dynamically adjust DRV_VOUT so the supply targets the vadj voltage. For PMIC mode, see REGHC_PMIC_DRV_VOUT.
  [3:2] REGHC_PMIC_DRV_VOUT — Setting for DRV_VOUT pin for PMIC mode. See REGHC_VADJ for calculation of vadj. 2'b00: DRV_VOUT=vccd*0.9/vadj; 2'b01: DRV_VOUT=vccd*0.8/vadj; 2'b10: DRV_VOUT=vccd*0.6/vadj; 2'b11: DRV_VOUT=vccd
  [0] REGHC_MODE — REGHC control mode: 0: external transistor connected, 1: external PMIC connected
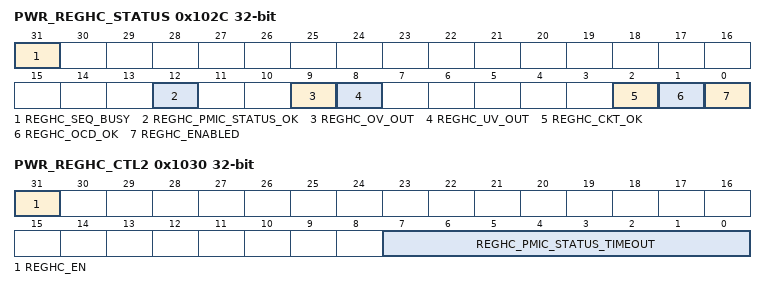
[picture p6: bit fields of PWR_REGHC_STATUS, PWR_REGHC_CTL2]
0x102C PWR_REGHC_STATUS ro — REGHC Status Register
  [31] REGHC_SEQ_BUSY — Indicates the REGHC enable/disable sequencer is busy transitioning to/from REGHC. 0: Sequencer is not busy; 1: Sequencer is busy either enabling or disabling REGHC.
  [12] REGHC_PMIC_STATUS_OK — Indicates the PMIC status is ok. This includes polarity adjustment according to REGHC_PMIC_STATUS_POLARITY. 0: PMIC status is not ok or PMIC input buffer is disabled (REGHC_PMIC_STATUS_INEN==0); 1: PMIC status input buffer is enabled and indicates ok
  [9] REGHC_OV_OUT
  [8] REGHC_UV_OUT
  [2] REGHC_CKT_OK — Indicates the REGHC circuit is enabled and operating. It does not indicate that the voltage and current are within required limits for robust operation. 0: REGHC circuit is not ready. This can occur if the REGHC circuit is disabled or if it was recently enabled. 1: REGHC circuit is enabled and operating.
  [1] REGHC_OCD_OK — Indicates the over-current detector is operating and the current drawn from REGHC is within limits. OCD is only a choice for transistor mode, and it is disabled for PMIC mode. 0: Current measurement exceeds limit or detector is OFF, 1: Current measurement within limit
  [0] REGHC_ENABLED — Indicates the state of the REGHC enable/disable sequencer. This bit is only valid when REGHC_SEQ_BUSY==0. 0: REGHC sequencer indicates REGHC is disabled. 1: REGHC sequencer indicates REGHC is enabled.
0x1030 PWR_REGHC_CTL2 — REGHC Control Register 2
  [31] REGHC_EN — Enable REGHC. This bit will not set if REGHC_CONFIGURED==0. Use PWR_REGHC_STATUS.ENABLED to know the actual status of REGHC. It will differ from this bit in the following cases: A) Do not enter DEEPSLEEP while the sequencer is busy (see PWR_REGHC_STATUS.REGHC_SEQ_BUSY). The hardware sequencer disables REGHC during DEEPSLEEP entry and enables it upon wakeup. B) The debugger requests the chip remain powered up. Hardware prevents REGHC from disabling when this bit is cleared. Hardware does not automatically enable REGHC in response to debugger power up request. If this bit is low when the debugger deasserts the power up request, the hardware sequencer will disable REGHC.
  [7:0] REGHC_PMIC_STATUS_TIMEOUT — Timeout while waiting for REGHC_PMIC_STATUS_OK==1 when switching to PMIC. 0: disables timeout. >0: enables timeout of REGHC_PMIC_STATUS_TIMEOUT*128us (nominal, clocked by IMO). Timeout expiration triggers reset.
